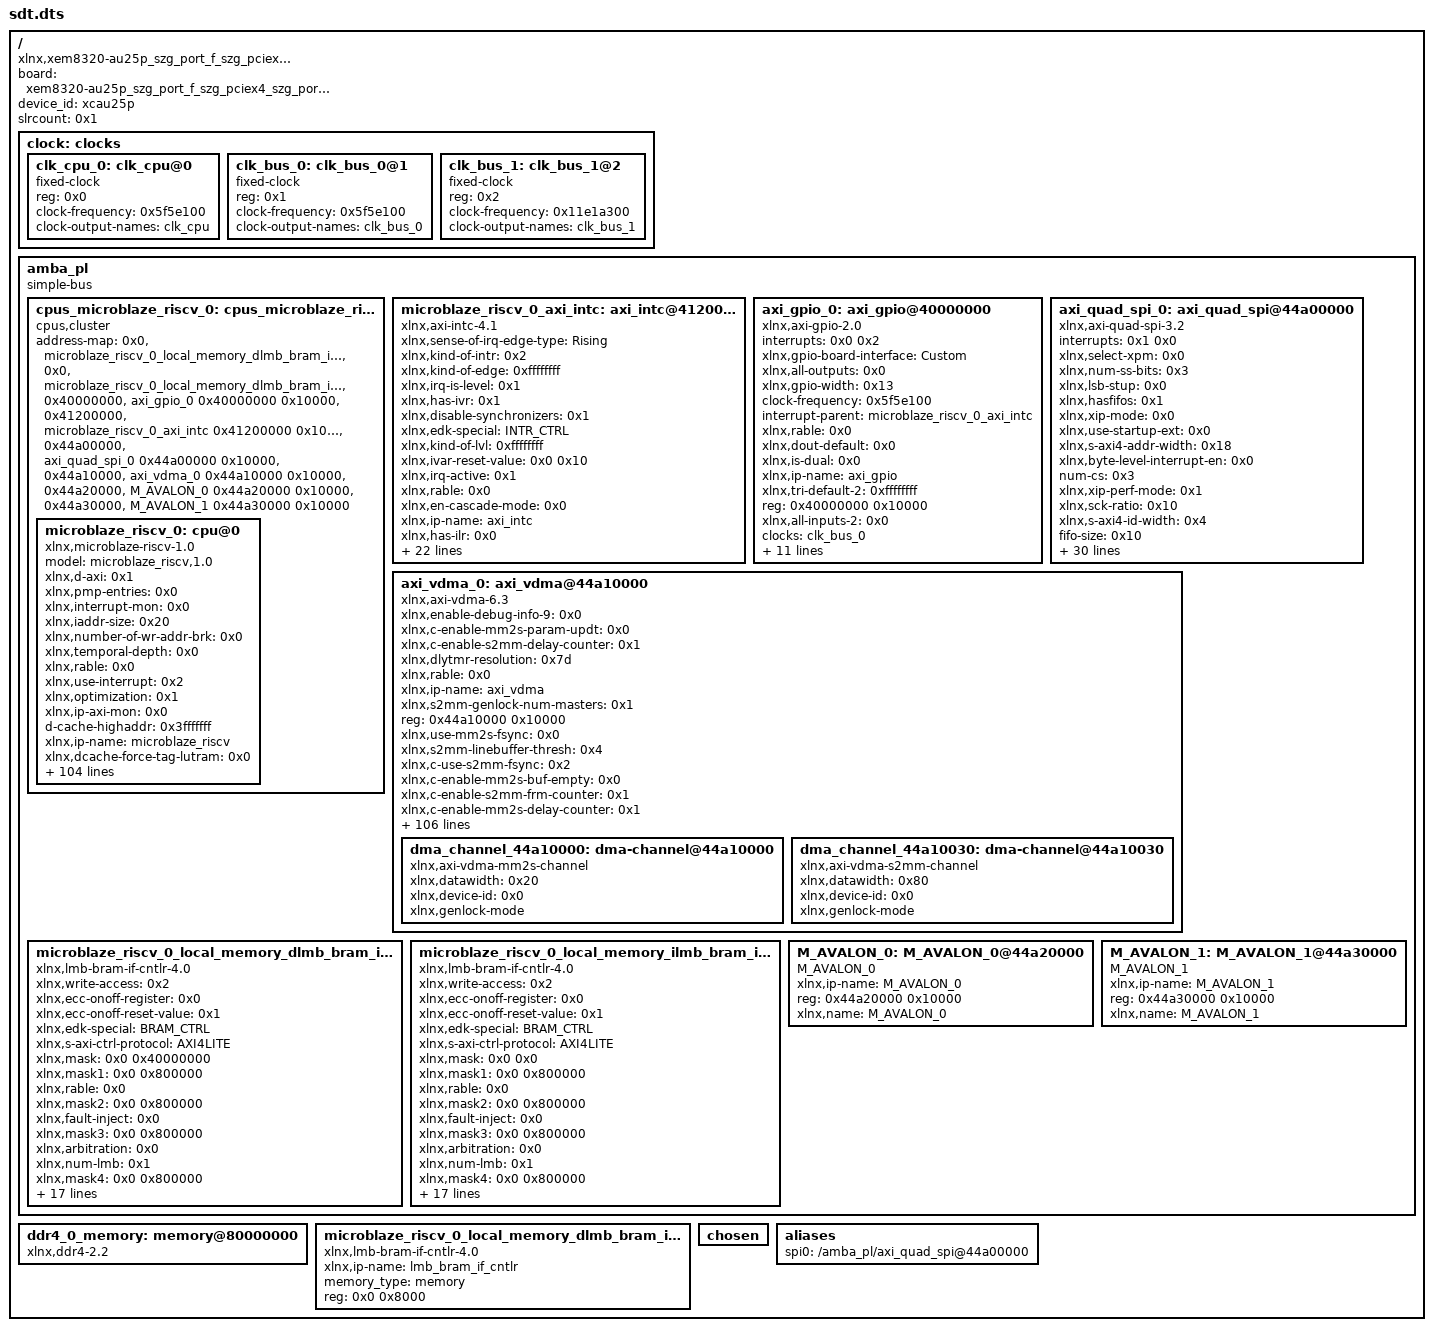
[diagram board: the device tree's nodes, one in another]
/dts-v1/;

/ {
        board = "xem8320-au25p_szg_port_f_szg_pciex4_szg_port_txr4";
        compatible = "xlnx,xem8320-au25p_szg_port_f_szg_pciex4_szg_port_txr4";
        device_id = "xcau25p";
        #address-cells = <0x1>;
        #size-cells = <0x1>;
        slrcount = <0x1>;

        clock: clocks {
                #address-cells = <0x1>;
                #size-cells = <0x0>;
                phandle = <0xc>;

                clk_cpu_0: clk_cpu@0 {
                        compatible = "fixed-clock";
                        reg = <0x0>;
                        clock-frequency = <0x5f5e100>;
                        clock-output-names = "clk_cpu";
                        #clock-cells = <0x0>;
                        phandle = <0xd>;
                };

                clk_bus_0: clk_bus_0@1 {
                        compatible = "fixed-clock";
                        reg = <0x1>;
                        clock-frequency = <0x5f5e100>;
                        clock-output-names = "clk_bus_0";
                        #clock-cells = <0x0>;
                        phandle = <0xa>;
                };

                clk_bus_1: clk_bus_1@2 {
                        compatible = "fixed-clock";
                        reg = <0x2>;
                        clock-frequency = <0x11e1a300>;
                        clock-output-names = "clk_bus_1";
                        #clock-cells = <0x0>;
                        phandle = <0xb>;
                };
        };

        amba_pl: amba_pl {
                ranges;
                compatible = "simple-bus";
                #address-cells = <0x1>;
                #size-cells = <0x1>;
                phandle = <0x9>;

                cpus_microblaze_riscv_0: cpus_microblaze_riscv@0 {
                        #cpu-mask-cells = <0x1>;
                        compatible = "cpus,cluster";
                        #address-cells = <0x1>;
                        #size-cells = <0x0>;
                        address-map = <0x0 &microblaze_riscv_0_local_memory_dlmb_bram_if_cntlr_memory 0x0 0x8000>,
                         <0x0 &microblaze_riscv_0_local_memory_dlmb_bram_if_cntlr 0x0 0x8000>,
                         <0x40000000 &axi_gpio_0 0x40000000 0x10000>,
                         <0x41200000 &microblaze_riscv_0_axi_intc 0x41200000 0x10000>,
                         <0x44a00000 &axi_quad_spi_0 0x44a00000 0x10000>,
                         <0x44a10000 &axi_vdma_0 0x44a10000 0x10000>,
                         <0x44a20000 &M_AVALON_0 0x44a20000 0x10000>,
                         <0x44a30000 &M_AVALON_1 0x44a30000 0x10000>;
                        #ranges-address-cells = <0x1>;
                        #ranges-size-cells = <0x1>;
                        phandle = <0xe>;

                        microblaze_riscv_0: cpu@0 {
                                model = "microblaze_riscv,1.0";
                                xlnx,d-axi = <0x1>;
                                xlnx,pmp-entries = <0x0>;
                                xlnx,interrupt-mon = <0x0>;
                                xlnx,iaddr-size = <0x20>;
                                xlnx,number-of-wr-addr-brk = <0x0>;
                                xlnx,temporal-depth = <0x0>;
                                xlnx,rable = <0x0>;
                                xlnx,use-interrupt = <0x2>;
                                xlnx,optimization = <0x1>;
                                xlnx,ip-axi-mon = <0x0>;
                                d-cache-highaddr = <0x3fffffff>;
                                xlnx,ip-name = "microblaze_riscv";
                                xlnx,dcache-force-tag-lutram = <0x0>;
                                xlnx,pc-width = <0xf>;
                                xlnx,interrupt-is-edge = <0x0>;
                                reg = <0x0>;
                                xlnx,async-interrupt = <0x1>;
                                xlnx,use-mmu = <0x0>;
                                xlnx,icache-victims = <0x0>;
                                xlnx,use-bitman-a = <0x0>;
                                xlnx,d-lmb-mon = <0x0>;
                                xlnx,d-lmb-protocol = <0x0>;
                                xlnx,use-bitman-b = <0x0>;
                                xlnx,use-bitman-c = <0x0>;
                                xlnx,dc-axi-mon = <0x0>;
                                xlnx,debug-trace-async-reset = <0x0>;
                                xlnx,trace = <0x0>;
                                xlnx,part = "xcau25p-ffvb676-2-e";
                                xlnx,use-config-reset = <0x0>;
                                xlnx,i-lmb-mon = <0x0>;
                                xlnx,dcache-byte-size = <0x1000>;
                                xlnx,ill-instr-exception = <0x2>;
                                compatible = "xlnx,microblaze-riscv-1.0", "xlnx,microblaze_riscv";
                                xlnx,data-size = <0x20>;
                                xlnx,fault-tolerant = <0x1>;
                                xlnx,use-sleep = <0x0>;
                                xlnx,debug-trace-size = <0x2000>;
                                xlnx,pmp-granularity = <0x2>;
                                xlnx,mmu-privileged-instr = <0x0>;
                                d-cache-line-size = <0x10>;
                                xlnx,d-lmb = <0x1>;
                                xlnx,enable-discrete-ports = <0x0>;
                                clock-frequency = <0x5f5e100>;
                                xlnx,debug-interface = <0x0>;
                                xlnx,use-ext-brk = <0x0>;
                                xlnx,daddr-size = <0x20>;
                                xlnx,debug-enabled = <0x1>;
                                xlnx,num-sync-ff-dbg-trace-clk = <0x2>;
                                xlnx,i-lmb-protocol = <0x0>;
                                xlnx,fsl-exception = <0x0>;
                                xlnx,use-extended-fsl-instr = <0x0>;
                                xlnx,dp-axi-mon = <0x0>;
                                xlnx,impid = <0x0 0x1>;
                                xlnx,branch-target-cache-size = <0x0>;
                                xlnx,dcache-use-writeback = <0x0>;
                                xlnx,use-bitman-s = <0x0>;
                                bus-handle = <0x9>;
                                xlnx,icache-line-len = <0x4>;
                                xlnx,base-vectors = <0x0 0x0>;
                                xlnx,ecc-use-ce-exception = <0x0>;
                                xlnx,use-dcache = <0x0>;
                                xlnx,use-barrel = <0x1>;
                                xlnx,edk-special = "microblaze_riscv";
                                xlnx,use-muldiv = <0x2>;
                                xlnx,addr-size = <0x20>;
                                xlnx,debug-external-trace = <0x0>;
                                xlnx,piaddr-size = <0x20>;
                                xlnx,misaligned-exceptions = <0x1>;
                                xlnx,use-bitman = <0x0>;
                                xlnx,num-sync-ff-clk-debug = <0x2>;
                                xlnx,debug-event-counters = <0x0>;
                                xlnx,use-atomic = <0x0>;
                                xlnx,i-axi = <0x0>;
                                xlnx,icache-streams = <0x0>;
                                xlnx,g-template-list = <0x1>;
                                xlnx,dcache-line-len = <0x4>;
                                xlnx,num-sync-ff-clk = <0x2>;
                                xlnx,num-sync-ff-dbg-clk = <0x1>;
                                xlnx,interconnect = <0x2>;
                                xlnx,hartid = <0x0 0x0>;
                                xlnx,debug-latency-counters = <0x0>;
                                xlnx,edk-iptype = "PROCESSOR";
                                xlnx,use-fpu = <0x0>;
                                xlnx,icache-byte-size = <0x2000>;
                                xlnx,edge-is-positive = <0x1>;
                                xlnx,use-icache = <0x0>;
                                d-cache-size = <0x1000>;
                                xlnx,async-wakeup = <0x3>;
                                xlnx,use-non-secure = <0x0>;
                                xlnx,number-of-rd-addr-brk = <0x0>;
                                d-cache-baseaddr = <0x0>;
                                xlnx,use-compression = <0x1>;
                                xlnx,avoid-primitives = <0x0>;
                                xlnx,use-counters = <0x1>;
                                xlnx,lockstep-slave = <0x0>;
                                xlnx,use-ext-nm-brk = <0x0>;
                                xlnx,pdaddr-size = <0x20>;
                                xlnx,instr-size = <0x20>;
                                interrupt-handle = <0x4>;
                                xlnx,i-lmb = <0x1>;
                                xlnx,lockstep-select = <0x0>;
                                xlnx,lmb-data-size = <0x20>;
                                xlnx,ic-axi-mon = <0x0>;
                                xlnx,num-sync-ff-clk-irq = <0x1>;
                                xlnx,fsl-links = <0x0>;
                                timebase-frequency = <0x5f5e100>;
                                xlnx,archid = <0x0 0x1>;
                                xlnx,icache-force-tag-lutram = <0x0>;
                                xlnx,dcache-data-width = <0x0>;
                                xlnx,dcache-victims = <0x0>;
                                xlnx,use-branch-target-cache = <0x0>;
                                xlnx,debug-profile-size = <0x0>;
                                xlnx,lockstep-master = <0x0>;
                                xlnx,freq = <0x5f5e100>;
                                xlnx,number-of-pc-brk = <0x1>;
                                xlnx,imprecise-exceptions = <0x0>;
                                xlnx,icache-data-width = <0x0>;
                                xlnx,debug-counter-width = <0x40>;
                                phandle = <0xf>;
                        };
                };

                microblaze_riscv_0_axi_intc: axi_intc@41200000 {
                        #interrupt-cells = <0x2>;
                        xlnx,sense-of-irq-edge-type = "Rising";
                        xlnx,kind-of-intr = <0x2>;
                        xlnx,kind-of-edge = <0xffffffff>;
                        xlnx,irq-is-level = <0x1>;
                        xlnx,has-ivr = <0x1>;
                        compatible = "xlnx,axi-intc-4.1", "xlnx,xps-intc-1.00.a";
                        xlnx,disable-synchronizers = <0x1>;
                        xlnx,edk-special = "INTR_CTRL";
                        xlnx,kind-of-lvl = <0xffffffff>;
                        xlnx,ivar-reset-value = <0x0 0x10>;
                        xlnx,irq-active = <0x1>;
                        xlnx,rable = <0x0>;
                        xlnx,en-cascade-mode = <0x0>;
                        xlnx,ip-name = "axi_intc";
                        xlnx,has-ilr = <0x0>;
                        reg = <0x41200000 0x10000>;
                        xlnx,addr-width = <0x20>;
                        xlnx,s-axi-aclk-freq-mhz = <0x64>;
                        xlnx,num-sw-intr = <0x0>;
                        xlnx,irq-connection = <0x0>;
                        xlnx,num-intr-inputs = <0x2>;
                        xlnx,has-sie = <0x1>;
                        xlnx,has-cie = <0x1>;
                        xlnx,enable-async = <0x0>;
                        xlnx,num-sync-ff = <0x2>;
                        xlnx,mb-clk-not-connected = <0x1>;
                        xlnx,has-ipr = <0x1>;
                        xlnx,edk-iptype = "PERIPHERAL";
                        xlnx,sense-of-irq-level-type = "Active_High";
                        xlnx,cascade-master = <0x0>;
                        xlnx,processor-clk-freq-mhz = <0x64>;
                        status = "okay";
                        xlnx,is-fast = <0x1>;
                        xlnx,has-fast = <0x1>;
                        xlnx,ivar-rst-val = <0x10>;
                        interrupt-controller;
                        xlnx,async-intr = <0xfffffffc>;
                        xlnx,name = "microblaze_riscv_0_axi_intc";
                        phandle = <0x4>;
                };

                axi_gpio_0: axi_gpio@40000000 {
                        #interrupt-cells = <0x2>;
                        interrupts = <0x0 0x2>;
                        xlnx,gpio-board-interface = "Custom";
                        compatible = "xlnx,axi-gpio-2.0", "xlnx,xps-gpio-1.00.a";
                        xlnx,all-outputs = <0x0>;
                        #gpio-cells = <0x2>;
                        xlnx,gpio-width = <0x13>;
                        clock-frequency = <0x5f5e100>;
                        interrupt-parent = <&microblaze_riscv_0_axi_intc>;
                        xlnx,rable = <0x0>;
                        xlnx,dout-default = <0x0>;
                        xlnx,is-dual = <0x0>;
                        xlnx,ip-name = "axi_gpio";
                        xlnx,tri-default-2 = <0xffffffff>;
                        reg = <0x40000000 0x10000>;
                        xlnx,all-inputs-2 = <0x0>;
                        clocks = <&clk_bus_0>;
                        xlnx,all-outputs-2 = <0x0>;
                        gpio-controller;
                        xlnx,interrupt-present = <0x1>;
                        xlnx,gpio2-board-interface = "Custom";
                        xlnx,edk-iptype = "PERIPHERAL";
                        xlnx,dout-default-2 = <0x0>;
                        xlnx,gpio2-width = <0x20>;
                        status = "okay";
                        clock-names = "s_axi_aclk";
                        interrupt-controller;
                        interrupt-names = "ip2intc_irpt";
                        xlnx,tri-default = <0x7e594>;
                        xlnx,name = "axi_gpio_0";
                        xlnx,all-inputs = <0x0>;
                        phandle = <0x3>;
                };

                axi_quad_spi_0: axi_quad_spi@44a00000 {
                        interrupts = <0x1 0x0>;
                        xlnx,select-xpm = <0x0>;
                        xlnx,num-ss-bits = <0x3>;
                        compatible = "xlnx,axi-quad-spi-3.2", "xlnx,xps-spi-2.00.a";
                        xlnx,lsb-stup = <0x0>;
                        xlnx,hasfifos = <0x1>;
                        xlnx,xip-mode = <0x0>;
                        xlnx,use-startup-ext = <0x0>;
                        xlnx,s-axi4-addr-width = <0x18>;
                        xlnx,byte-level-interrupt-en = <0x0>;
                        num-cs = <0x3>;
                        xlnx,xip-perf-mode = <0x1>;
                        xlnx,sck-ratio = <0x10>;
                        xlnx,s-axi4-id-width = <0x4>;
                        fifo-size = <0x10>;
                        interrupt-parent = <&microblaze_riscv_0_axi_intc>;
                        xlnx,rable = <0x0>;
                        xlnx,multiples16 = <0x1>;
                        xlnx,master-mode = <0x1>;
                        xlnx,shared-startup = <0x0>;
                        xlnx,ip-name = "axi_quad_spi";
                        xlnx,qspi-board-interface = "Custom";
                        xlnx,new-seq-en = <0x1>;
                        reg = <0x44a00000 0x10000>;
                        xlnx,dual-quad-mode = <0x0>;
                        bits-per-word = <0x8>;
                        xlnx,num-transfer-bits = <0x8>;
                        xlnx,spi-memory = <0x1>;
                        xlnx,s-axi4-data-width = <0x20>;
                        xlnx,edk-iptype = "PERIPHERAL";
                        xlnx,slaveonly = <0x0>;
                        xlnx,use-startup-int = <0x0>;
                        xlnx,use-startup = <0x0>;
                        xlnx,type-of-axi4-interface = <0x0>;
                        xlnx,async-clk = <0x0>;
                        xlnx,spi-mode = <0x0>;
                        xlnx,sck-ratio1 = <0x1>;
                        status = "okay";
                        xlnx,fifo-depth = <0x10>;
                        xlnx,uc-family = <0x1>;
                        xlnx,spi-mem-addr-bits = <0x18>;
                        xlnx,axi-interface = <0x0>;
                        interrupt-names = "ip2intc_irpt";
                        xlnx,Axi4-address = <0x0>;
                        xlnx,sub-family = "kintexuplus";
                        xlnx,name = "axi_quad_spi_0";
                        xlnx,fifo-included = <0x1>;
                        phandle = <0x5>;
                };

                axi_vdma_0: axi_vdma@44a10000 {
                        xlnx,enable-debug-info-9 = <0x0>;
                        xlnx,c-enable-mm2s-param-updt = <0x0>;
                        xlnx,c-enable-s2mm-delay-counter = <0x1>;
                        xlnx,dlytmr-resolution = <0x7d>;
                        xlnx,rable = <0x0>;
                        xlnx,ip-name = "axi_vdma";
                        xlnx,s2mm-genlock-num-masters = <0x1>;
                        reg = <0x44a10000 0x10000>;
                        xlnx,use-mm2s-fsync = <0x0>;
                        xlnx,s2mm-linebuffer-thresh = <0x4>;
                        xlnx,c-use-s2mm-fsync = <0x2>;
                        xlnx,c-enable-mm2s-buf-empty = <0x0>;
                        xlnx,c-enable-s2mm-frm-counter = <0x1>;
                        xlnx,c-enable-mm2s-delay-counter = <0x1>;
                        xlnx,c-dlytmr-resolution = <0x7d>;
                        xlnx,c-enable-s2mm-buf-full = <0x0>;
                        xlnx,dynamic-resolution = <0x1>;
                        xlnx,s2mm-sof-enable = <0x1>;
                        xlnx,mm2s-genlock-num-masters = <0x1>;
                        xlnx,c-s2mm-genlock-num-masters = <0x1>;
                        xlnx,c-enable-s2mm-fsync-out = <0x0>;
                        xlnx,mm2s-linebuffer-thresh = <0x4>;
                        xlnx,c-use-mm2s-fsync = <0x0>;
                        xlnx,c-s2mm-linebuffer-thresh = <0x4>;
                        xlnx,c-enable-mm2s-frm-counter = <0x1>;
                        compatible = "xlnx,axi-vdma-6.3", "xlnx,axi-vdma-1.00.a";
                        xlnx,c-m-axis-mm2s-tdata-width = <0x20>;
                        clock-frequency = <0x5f5e100 0x11e1a300 0x11e1a300 0x11e1a300 0x11e1a300>;
                        xlnx,c-enable-all = <0x0>;
                        xlnx,s2mm-max-burst-length = <0x8>;
                        xlnx,c-dynamic-resolution = <0x1>;
                        xlnx,c-enable-s2mm-rst-out = <0x0>;
                        xlnx,mm2s-sof-enable = <0x1>;
                        xlnx,include-s2mm-dre = <0x0>;
                        xlnx,c-s2mm-sof-enable = <0x1>;
                        xlnx,c-enable-mm2s-fsync-out = <0x0>;
                        xlnx,c-mm2s-genlock-num-masters = <0x1>;
                        xlnx,c-mm2s-linebuffer-thresh = <0x4>;
                        xlnx,c-enable-tstvec = <0x0>;
                        xlnx,mm2s-max-burst-length = <0x8>;
                        xlnx,c-s2mm-max-burst-length = <0x8>;
                        status = "okay";
                        xlnx,c-enable-mm2s-rst-out = <0x0>;
                        xlnx,include-mm2s-dre = <0x0>;
                        xlnx,c-include-s2mm-dre = <0x0>;
                        xlnx,c-mm2s-sof-enable = <0x1>;
                        xlnx,name = "axi_vdma_0";
                        xlnx,c-enable-s2mm-frmstr-reg = <0x0>;
                        xlnx,c-include-sg = <0x0>;
                        xlnx,flush-on-fsync = <0x1>;
                        xlnx,c-m-axi-s2mm-data-width = <0x80>;
                        xlnx,c-enable-s2mm-sts-reg = <0x1>;
                        xlnx,include-s2mm-sf = <0x1>;
                        xlnx,c-mm2s-max-burst-length = <0x8>;
                        xlnx,s2mm-linebuffer-depth = <0x200>;
                        xlnx,include-s2mm = <0x1>;
                        xlnx,c-include-mm2s-dre = <0x0>;
                        clocks = <&clk_bus_0>,
                         <&clk_bus_1>,
                         <&clk_bus_1>,
                         <&clk_bus_1>,
                         <&clk_bus_1>;
                        xlnx,c-enable-mm2s-frmstr-reg = <0x0>;
                        xlnx,enable-debug-info-10 = <0x0>;
                        xlnx,addrwidth = <0x20>;
                        xlnx,enable-debug-info-11 = <0x0>;
                        xlnx,enable-debug-info-12 = <0x1>;
                        xlnx,edk-iptype = "PERIPHERAL";
                        xlnx,c-flush-on-fsync = <0x1>;
                        xlnx,c-m-axi-mm2s-data-width = <0x40>;
                        xlnx,use-fsync = <0x1>;
                        xlnx,s2mm-genlock-repeat-en = <0x1>;
                        xlnx,enable-vert-flip = <0x0>;
                        xlnx,enable-debug-info-13 = <0x0>;
                        xlnx,include-mm2s-sf = <0x0>;
                        xlnx,include-internal-genlock = <0x1>;
                        xlnx,enable-debug-info-14 = <0x1>;
                        xlnx,c-include-s2mm-sf = <0x1>;
                        clock-names = "s_axi_lite_aclk", "m_axi_mm2s_aclk", "m_axi_mm2s_aclk", "m_axi_s2mm_aclk", "m_axi_s2mm_aclk";
                        xlnx,enable-debug-info-15 = <0x1>;
                        xlnx,mm2s-linebuffer-depth = <0x200>;
                        xlnx,include-mm2s = <0x1>;
                        xlnx,c-single-interface = <0x0>;
                        xlnx,c-s2mm-linebuffer-depth = <0x200>;
                        xlnx,c-addr-width = <0x20>;
                        xlnx,c-include-s2mm = <0x1>;
                        xlnx,s2mm-genlock-mode = <0x2>;
                        xlnx,c-s-axis-s2mm-tdata-width = <0x80>;
                        xlnx,flush-fsync = <0x1>;
                        xlnx,select-xpm = <0x0>;
                        xlnx,s2mm-data-width = <0x80>;
                        xlnx,num-fstores = <0x3>;
                        xlnx,enable-vidparam-reads = <0x1>;
                        xlnx,mm2s-genlock-repeat-en = <0x0>;
                        xlnx,c-use-fsync = <0x1>;
                        xlnx,c-s2mm-genlock-repeat-en = <0x1>;
                        xlnx,c-enable-vert-flip = <0x0>;
                        xlnx,prmry-is-aclk-async = <0x1>;
                        xlnx,c-include-internal-genlock = <0x1>;
                        xlnx,c-include-mm2s-sf = <0x0>;
                        xlnx,s2mm-tdata-width = <0x80>;
                        xlnx,enable-vidprmtr-reads = <0x1>;
                        xlnx,c-include-mm2s = <0x1>;
                        xlnx,c-mm2s-linebuffer-depth = <0x200>;
                        xlnx,mm2s-genlock-mode = <0x3>;
                        xlnx,enable-debug-info-0 = <0x0>;
                        xlnx,enable-debug-all = <0x0>;
                        xlnx,c-s2mm-genlock-mode = <0x2>;
                        xlnx,enable-debug-info-1 = <0x0>;
                        xlnx,mm2s-data-width = <0x40>;
                        xlnx,enable-debug-info-2 = <0x0>;
                        xlnx,c-enable-s2mm-param-updt = <0x0>;
                        xlnx,c-num-fstores = <0x3>;
                        xlnx,enable-debug-info-3 = <0x0>;
                        xlnx,enable-debug-info-4 = <0x0>;
                        xlnx,c-mm2s-genlock-repeat-en = <0x0>;
                        xlnx,enable-debug-info-5 = <0x0>;
                        xlnx,c-prmry-is-aclk-async = <0x1>;
                        xlnx,mm2s-tdata-width = <0x20>;
                        xlnx,enable-debug-info-6 = <0x1>;
                        xlnx,enable-debug-info-7 = <0x1>;
                        xlnx,c-enable-vidprmtr-reads = <0x1>;
                        xlnx,use-s2mm-fsync = <0x2>;
                        xlnx,enable-debug-info-8 = <0x0>;
                        xlnx,c-mm2s-genlock-mode = <0x3>;
                        phandle = <0x6>;

                        dma_channel_44a10000: dma-channel@44a10000 {
                                xlnx,datawidth = <0x20>;
                                xlnx,device-id = <0x0>;
                                compatible = "xlnx,axi-vdma-mm2s-channel";
                                xlnx,genlock-mode;
                                phandle = <0x10>;
                        };

                        dma_channel_44a10030: dma-channel@44a10030 {
                                xlnx,datawidth = <0x80>;
                                xlnx,device-id = <0x0>;
                                compatible = "xlnx,axi-vdma-s2mm-channel";
                                xlnx,genlock-mode;
                                phandle = <0x11>;
                        };
                };

                microblaze_riscv_0_local_memory_dlmb_bram_if_cntlr: lmb_bram_if_cntlr@0 {
                        xlnx,write-access = <0x2>;
                        compatible = "xlnx,lmb-bram-if-cntlr-4.0";
                        xlnx,ecc-onoff-register = <0x0>;
                        xlnx,ecc-onoff-reset-value = <0x1>;
                        xlnx,edk-special = "BRAM_CTRL";
                        xlnx,s-axi-ctrl-protocol = "AXI4LITE";
                        xlnx,mask = <0x0 0x40000000>;
                        xlnx,mask1 = <0x0 0x800000>;
                        xlnx,rable = <0x0>;
                        xlnx,mask2 = <0x0 0x800000>;
                        xlnx,fault-inject = <0x0>;
                        xlnx,mask3 = <0x0 0x800000>;
                        xlnx,arbitration = <0x0>;
                        xlnx,num-lmb = <0x1>;
                        xlnx,mask4 = <0x0 0x800000>;
                        reg = <0x0 0x8000>;
                        xlnx,s-axi-ctrl-addr-width = <0x20>;
                        xlnx,mask5 = <0x0 0x800000>;
                        xlnx,ecc-status-registers = <0x0>;
                        xlnx,mask6 = <0x0 0x800000>;
                        xlnx,lmb-protocol = <0x0>;
                        xlnx,ce-counter-width = <0x0>;
                        xlnx,mask7 = <0x0 0x800000>;
                        xlnx,ecc = <0x1>;
                        xlnx,lmb-dwidth = <0x20>;
                        xlnx,interconnect = <0x0>;
                        xlnx,ce-failing-registers = <0x0>;
                        xlnx,edk-iptype = "PERIPHERAL";
                        xlnx,ue-failing-registers = <0x0>;
                        xlnx,s-axi-ctrl-data-width = <0x20>;
                        xlnx,bram-awidth = <0x20>;
                        xlnx,lmb-awidth = <0x20>;
                        phandle = <0x2>;
                };

                microblaze_riscv_0_local_memory_ilmb_bram_if_cntlr: lmb_bram_if_cntlr@1 {
                        xlnx,write-access = <0x2>;
                        compatible = "xlnx,lmb-bram-if-cntlr-4.0";
                        xlnx,ecc-onoff-register = <0x0>;
                        xlnx,ecc-onoff-reset-value = <0x1>;
                        xlnx,edk-special = "BRAM_CTRL";
                        xlnx,s-axi-ctrl-protocol = "AXI4LITE";
                        xlnx,mask = <0x0 0x0>;
                        xlnx,mask1 = <0x0 0x800000>;
                        xlnx,rable = <0x0>;
                        xlnx,mask2 = <0x0 0x800000>;
                        xlnx,fault-inject = <0x0>;
                        xlnx,mask3 = <0x0 0x800000>;
                        xlnx,arbitration = <0x0>;
                        xlnx,num-lmb = <0x1>;
                        xlnx,mask4 = <0x0 0x800000>;
                        reg = <0x0 0x8000>;
                        xlnx,s-axi-ctrl-addr-width = <0x20>;
                        xlnx,mask5 = <0x0 0x800000>;
                        xlnx,ecc-status-registers = <0x0>;
                        xlnx,mask6 = <0x0 0x800000>;
                        xlnx,lmb-protocol = <0x0>;
                        xlnx,ce-counter-width = <0x0>;
                        xlnx,mask7 = <0x0 0x800000>;
                        xlnx,ecc = <0x1>;
                        xlnx,lmb-dwidth = <0x20>;
                        xlnx,interconnect = <0x0>;
                        xlnx,ce-failing-registers = <0x0>;
                        xlnx,edk-iptype = "PERIPHERAL";
                        xlnx,ue-failing-registers = <0x0>;
                        xlnx,s-axi-ctrl-data-width = <0x20>;
                        xlnx,bram-awidth = <0x20>;
                        xlnx,lmb-awidth = <0x20>;
                        phandle = <0x12>;
                };

                M_AVALON_0: M_AVALON_0@44a20000 {
                        status = "okay";
                        compatible = "M_AVALON_0";
                        xlnx,ip-name = "M_AVALON_0";
                        reg = <0x44a20000 0x10000>;
                        xlnx,name = "M_AVALON_0";
                        phandle = <0x7>;
                };

                M_AVALON_1: M_AVALON_1@44a30000 {
                        status = "okay";
                        compatible = "M_AVALON_1";
                        xlnx,ip-name = "M_AVALON_1";
                        reg = <0x44a30000 0x10000>;
                        xlnx,name = "M_AVALON_1";
                        phandle = <0x8>;
                };
        };

        ddr4_0_memory: memory@80000000 {
                compatible = "xlnx,ddr4-2.2";
                phandle = <0x13>;
        };

        microblaze_riscv_0_local_memory_dlmb_bram_if_cntlr_memory: memory@0 {
                compatible = "xlnx,lmb-bram-if-cntlr-4.0";
                xlnx,ip-name = "lmb_bram_if_cntlr";
                device_type = "memory";
                memory_type = "memory";
                reg = <0x0 0x8000>;
                phandle = <0x1>;
        };

        chosen {
        };

        aliases {
                spi0 = "/amba_pl/axi_quad_spi@44a00000";
        };

        __symbols__ {
                clock = "/clocks";
                clk_cpu_0 = "/clocks/clk_cpu@0";
                clk_bus_0 = "/clocks/clk_bus_0@1";
                clk_bus_1 = "/clocks/clk_bus_1@2";
                amba_pl = "/amba_pl";
                cpus_microblaze_riscv_0 = "/amba_pl/cpus_microblaze_riscv@0";
                microblaze_riscv_0 = "/amba_pl/cpus_microblaze_riscv@0/cpu@0";
                microblaze_riscv_0_axi_intc = "/amba_pl/axi_intc@41200000";
                axi_gpio_0 = "/amba_pl/axi_gpio@40000000";
                axi_quad_spi_0 = "/amba_pl/axi_quad_spi@44a00000";
                axi_vdma_0 = "/amba_pl/axi_vdma@44a10000";
                dma_channel_44a10000 = "/amba_pl/axi_vdma@44a10000/dma-channel@44a10000";
                dma_channel_44a10030 = "/amba_pl/axi_vdma@44a10000/dma-channel@44a10030";
                microblaze_riscv_0_local_memory_dlmb_bram_if_cntlr = "/amba_pl/lmb_bram_if_cntlr@0";
                microblaze_riscv_0_local_memory_ilmb_bram_if_cntlr = "/amba_pl/lmb_bram_if_cntlr@1";
                M_AVALON_0 = "/amba_pl/M_AVALON_0@44a20000";
                M_AVALON_1 = "/amba_pl/M_AVALON_1@44a30000";
                ddr4_0_memory = "/memory@80000000";
                microblaze_riscv_0_local_memory_dlmb_bram_if_cntlr_memory = "/memory@0";
        };
};
